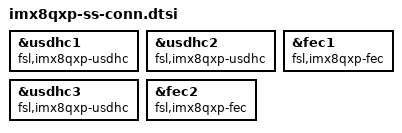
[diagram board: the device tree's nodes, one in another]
&usdhc1 {
	compatible = "fsl,imx8qxp-usdhc", "fsl,imx7d-usdhc";
};
&usdhc2 {
	compatible = "fsl,imx8qxp-usdhc", "fsl,imx7d-usdhc";
};
&usdhc3 {
	compatible = "fsl,imx8qxp-usdhc", "fsl,imx7d-usdhc";
};
&fec1 {
	compatible = "fsl,imx8qxp-fec", "fsl,imx8qm-fec", "fsl,imx6sx-fec";
};
&fec2 {
	compatible = "fsl,imx8qxp-fec", "fsl,imx8qm-fec", "fsl,imx6sx-fec";
};
